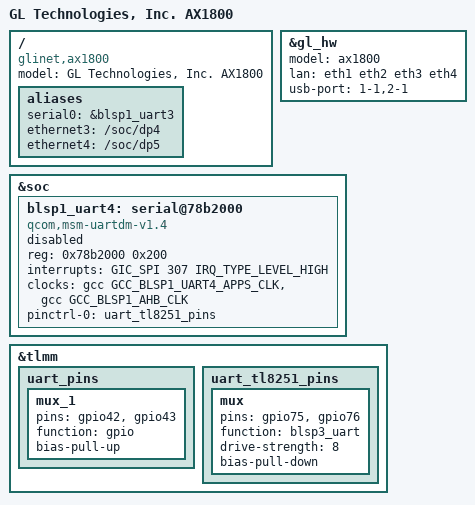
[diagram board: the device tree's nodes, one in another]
/dts-v1/;
/*
 * Copyright (c) 2019, The Linux Foundation. All rights reserved.
 *
 * Permission to use, copy, modify, and/or distribute this software for any
 * purpose with or without fee is hereby granted, provided that the above
 * copyright notice and this permission notice appear in all copies.
 *
 * THE SOFTWARE IS PROVIDED "AS IS" AND THE AUTHOR DISCLAIMS ALL WARRANTIES
 * WITH REGARD TO THIS SOFTWARE INCLUDING ALL IMPLIED WARRANTIES OF
 * MERCHANTABILITY AND FITNESS. IN NO EVENT SHALL THE AUTHOR BE LIABLE FOR
 * ANY SPECIAL, DIRECT, INDIRECT, OR CONSEQUENTIAL DAMAGES OR ANY DAMAGES
 * WHATSOEVER RESULTING FROM LOSS OF USE, DATA OR PROFITS, WHETHER IN AN
 * ACTION OF CONTRACT, NEGLIGENCE OR OTHER TORTIOUS ACTION, ARISING OUT OF
 * OR IN CONNECTION WITH THE USE OR PERFORMANCE OF THIS SOFTWARE.
 */

#include "qcom-ipq6018-gl-ax1800.dtsi"

/ {
	model = "GL Technologies, Inc. AX1800";
	compatible = "glinet,ax1800", "qcom,ipq6018-cp03", "qcom,ipq6018";

	aliases {
		serial0 = &blsp1_uart3; //system uart = ttyMSM0
		ethernet3 = "/soc/dp4";
		ethernet4 = "/soc/dp5";
	};
};

&gl_hw {
	model = "ax1800";
	lan = "eth1 eth2 eth3 eth4";
	usb-port = "1-1,2-1";
};

&soc {
	blsp1_uart4: serial@78b2000 {
		compatible = "qcom,msm-uartdm-v1.4", "qcom,msm-uartdm";
		reg = <0x78b2000 0x200>;
		interrupts = <GIC_SPI 307 IRQ_TYPE_LEVEL_HIGH>;
		clocks = <&gcc GCC_BLSP1_UART4_APPS_CLK>,
			<&gcc GCC_BLSP1_AHB_CLK>;
		clock-names = "core", "iface";
		status = "disabled";
	};
};

&tlmm {
	uart_pins: uart_pins {
		mux_1 {
			pins = "gpio42", "gpio43"; // i2c
			function = "gpio";
			bias-pull-up;
		};
	};
	uart_tl8251_pins: uart_tl8251_pins {
		mux {
			pins = "gpio75", "gpio76"; // gpio 77 reset tl8251
			function = "blsp3_uart";
			drive-strength = <8>;
			bias-pull-down;
		};
	};
};

&blsp1_uart4 {
	pinctrl-0 = <&uart_tl8251_pins>;
	pinctrl-names = "default";
	status = "disabled";
};
